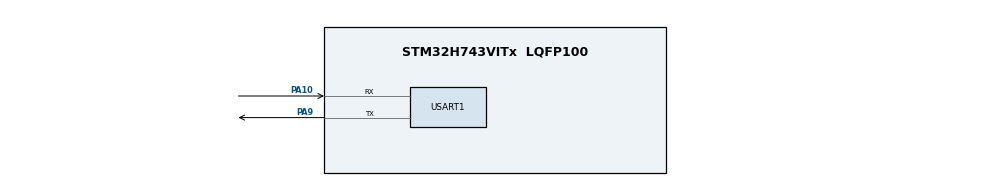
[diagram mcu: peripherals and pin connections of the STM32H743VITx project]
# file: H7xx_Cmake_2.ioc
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CORTEX_M7.default_mode_Activation=1
Mcu.Family=STM32H7
Mcu.Name=STM32H743VITx
Mcu.Package=LQFP100
NVIC.PriorityGroup=NVIC_PRIORITYGROUP_4
PA10.Mode=Asynchronous
PA10.Signal=USART1_RX
PA9.Mode=Asynchronous
PA9.Signal=USART1_TX
PH0-OSC_IN\ (PH0).Mode=HSE-External-Oscillator
PH0-OSC_IN\ (PH0).Signal=RCC_OSC_IN
PH1-OSC_OUT\ (PH1).Mode=HSE-External-Oscillator
PH1-OSC_OUT\ (PH1).Signal=RCC_OSC_OUT
ProjectManager.HeapSize=0x200
ProjectManager.StackSize=0x400
ProjectManager.TargetToolchain=Makefile
RCC.ADCFreq_Value=129000000
RCC.APB1Freq_Value=100000000
RCC.APB2Freq_Value=100000000
RCC.APB3Freq_Value=100000000
RCC.APB4Freq_Value=100000000
RCC.CortexFreq_Value=400000000
RCC.D1PPRE=RCC_APB3_DIV2
RCC.D2PPRE1=RCC_APB1_DIV2
RCC.D2PPRE2=RCC_APB2_DIV2
RCC.D3PPRE=RCC_APB4_DIV2
RCC.DIVM1=4
RCC.DIVN1=50
RCC.HCLKFreq_Value=200000000
RCC.HPRE=RCC_HCLK_DIV2
RCC.PLL2FRACN=0
RCC.PLL3FRACN=0
RCC.PLLFRACN=0
RCC.SYSCLKFreq_VALUE=400000000
RCC.SYSCLKSource=RCC_SYSCLKSOURCE_PLLCLK
RCC.USBFreq_Value=400000000
USART1.VirtualMode-Asynchronous=VM_ASYNC
board=custom

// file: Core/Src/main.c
/* USER CODE BEGIN Header */
/**
  ******************************************************************************
  * @file           : main.c
  * @brief          : Main program body
  ******************************************************************************
  * @attention
  *
  * Copyright (c) 2024 STMicroelectronics.
  * All rights reserved.
  *
  * This software is licensed under terms that can be found in the LICENSE file
  * in the root directory of this software component.
  * If no LICENSE file comes with this software, it is provided AS-IS.
  *
  ******************************************************************************
  */
/* USER CODE END Header */
#include "main.h"
#include "usart.h"
#include "gpio.h"

/* USER CODE BEGIN Includes */
#include "stdio.h"
#include "lcd.h"
#include "lcd_init.h"
#include "QSPI.h"
#include "lvgl.h"
/* USER CODE END Includes */

void SystemClock_Config(void);

/* USER CODE BEGIN 0 */
void CPU_CACHE_ENBALE()
{
  /* Enable I-Cache */
  SCB_EnableICache();

  /* Enable D-Cache */
  //SCB_EnableDCache();
}
/* USER CODE END 0 */

int main(void)
{

  /* MCU Configuration--------------------------------------------------------*/

  /* Reset of all peripherals, Initializes the Flash interface and the Systick. */
  HAL_Init();

  /* USER CODE BEGIN Init */
  CPU_CACHE_ENBALE(); //开启CPU缓存
  /* USER CODE END Init */

  /* Configure the system clock */
  SystemClock_Config();

  /* Initialize all configured peripherals */
  MX_GPIO_Init();
  MX_USART1_UART_Init();
  /* USER CODE BEGIN 2 */
  QSPI_GPIOInit();
  QSPI_Init();
  //LCD_Init();
  lv_init();
  lv_port_disp_init();
  lv_demo_stress();
  /* USER CODE END 2 */

  /* Infinite loop */
  while (1)
  {

    /* USER CODE BEGIN 3 */
    // LCD_Fill(0,0,360,360,0xff00);
    // HAL_Delay(50);
    // LCD_Fill(0,0,360,360,0xef10);
    // HAL_Delay(50);
    // LCD_Fill(0,0,360,360,0xdf20);
    // HAL_Delay(50);
    // LCD_Fill(0,0,360,360,0xcf30);
    // HAL_Delay(50);
    // LCD_Fill(0,0,360,360,0xbf40);
    // HAL_Delay(50);
    // LCD_Fill(0,0,360,360,0xaf50);
    // HAL_Delay(50);
    // LCD_Fill(0,0,360,360,0x9f60);
    lv_task_handler();
    printf("hello world!\r\n");
  }
  /* USER CODE END 3 */
}

void SystemClock_Config(void)
{
  RCC_OscInitTypeDef RCC_OscInitStruct = {0};
  RCC_ClkInitTypeDef RCC_ClkInitStruct = {0};

  /** Supply configuration update enable
  */
  HAL_PWREx_ConfigSupply(PWR_LDO_SUPPLY);

  /** Configure the main internal regulator output voltage
  */
  __HAL_PWR_VOLTAGESCALING_CONFIG(PWR_REGULATOR_VOLTAGE_SCALE1);

  while(!__HAL_PWR_GET_FLAG(PWR_FLAG_VOSRDY)) {}

  /** Initializes the RCC Oscillators according to the specified parameters
  * in the RCC_OscInitTypeDef structure.
  */
  RCC_OscInitStruct.OscillatorType = RCC_OSCILLATORTYPE_HSI;
  RCC_OscInitStruct.HSIState = RCC_HSI_DIV1;
  RCC_OscInitStruct.HSICalibrationValue = RCC_HSICALIBRATION_DEFAULT;
  RCC_OscInitStruct.PLL.PLLState = RCC_PLL_ON;
  RCC_OscInitStruct.PLL.PLLSource = RCC_PLLSOURCE_HSI;
  RCC_OscInitStruct.PLL.PLLM = 4;
  RCC_OscInitStruct.PLL.PLLN = 50;
  RCC_OscInitStruct.PLL.PLLP = 2;
  RCC_OscInitStruct.PLL.PLLQ = 2;
  RCC_OscInitStruct.PLL.PLLR = 2;
  RCC_OscInitStruct.PLL.PLLRGE = RCC_PLL1VCIRANGE_3;
  RCC_OscInitStruct.PLL.PLLVCOSEL = RCC_PLL1VCOWIDE;
  RCC_OscInitStruct.PLL.PLLFRACN = 0;
  if (HAL_RCC_OscConfig(&RCC_OscInitStruct) != HAL_OK)
  {
    Error_Handler();
  }

  /** Initializes the CPU, AHB and APB buses clocks
  */
  RCC_ClkInitStruct.ClockType = RCC_CLOCKTYPE_HCLK|RCC_CLOCKTYPE_SYSCLK
                              |RCC_CLOCKTYPE_PCLK1|RCC_CLOCKTYPE_PCLK2
                              |RCC_CLOCKTYPE_D3PCLK1|RCC_CLOCKTYPE_D1PCLK1;
  RCC_ClkInitStruct.SYSCLKSource = RCC_SYSCLKSOURCE_PLLCLK;
  RCC_ClkInitStruct.SYSCLKDivider = RCC_SYSCLK_DIV1;
  RCC_ClkInitStruct.AHBCLKDivider = RCC_HCLK_DIV2;
  RCC_ClkInitStruct.APB3CLKDivider = RCC_APB3_DIV2;
  RCC_ClkInitStruct.APB1CLKDivider = RCC_APB1_DIV2;
  RCC_ClkInitStruct.APB2CLKDivider = RCC_APB2_DIV2;
  RCC_ClkInitStruct.APB4CLKDivider = RCC_APB4_DIV2;

  if (HAL_RCC_ClockConfig(&RCC_ClkInitStruct, FLASH_LATENCY_2) != HAL_OK)
  {
    Error_Handler();
  }
}

void Error_Handler(void)
{
  __disable_irq();
  while (1)
  {
  }
}
